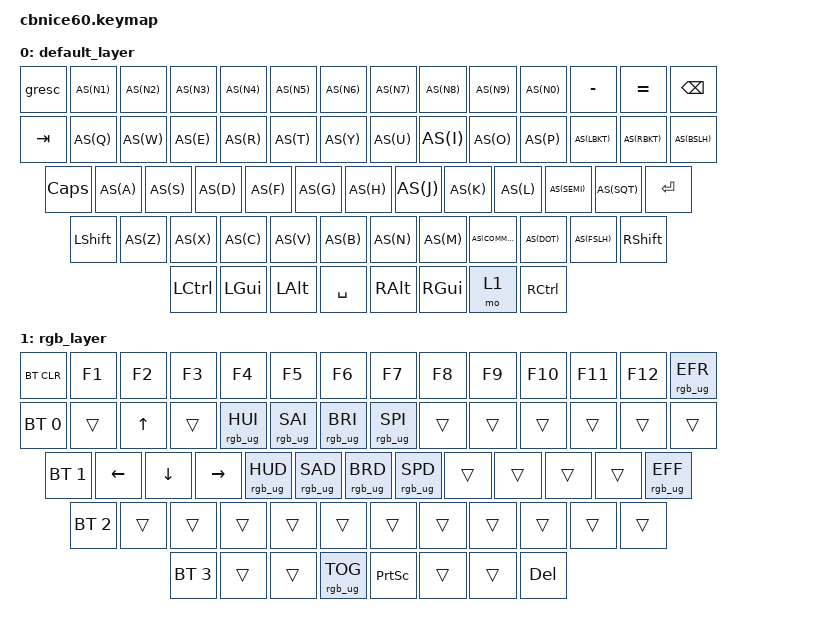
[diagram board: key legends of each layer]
/*
 * Copyright (c) 2021 Nick Winans
 *
 * SPDX-License-Identifier: MIT
 */

#include <behaviors.dtsi>
#include <dt-bindings/zmk/keys.h>
#include <dt-bindings/zmk/rgb.h>
#include <dt-bindings/zmk/bt.h>
#include <dt-bindings/zmk/outputs.h>
#include <dt-bindings/zmk/reset.h>
#include <dt-bindings/zmk/ext_power.h>

/ {
    behaviors {
        as: auto_shift {
            compatible = "zmk,behavior-hold-tap";
            label = "AUTO_SHIFT";
            #binding-cells = <2>;
            tapping_term_ms = <135>;
            quick_tap_ms = <0>;
            flavor = "tap-preferred";
            bindings = <&kp>, <&kp>;
        };
    };
	keymap {
		compatible = "zmk,keymap";
		
		default_layer {
// ------------------------------------------------------------------------------------------
// | ESC |  1  |  2  |  3  |  4  |  5  |  6  |  7  |  8  |  9  |  0  |  -  |  =  |   BKSP   |
// | TAB  |  Q  |  W  |  E  |  R  |  T  |  Y  |  U  |  I  |  O  |  P  |  [  |  ]  |   "|"   |
// | CAPS  |  A  |  S  |  D  |  F  |  G  |  H  |  J  |  K  |  L  |  ;  |  '  |     ENTER    |
// |  SHIFT  |  Z  |  X  |  C  |  V  |  B  |  N  |  M  |  ,  |  .  |  /  |      SHIFT       |
// |  CTL  |  WIN  |  ALT  |            SPACE              |  ALT  |  WIN  |  MO(1) |  CTL  |
// ------------------------------------------------------------------------------------------
			bindings = <
	&gresc  AS(N1) AS(N2) AS(N3) AS(N4) AS(N5) AS(N6)  AS(N7) AS(N8)  AS(N9)  AS(N0) &kp MINUS &kp EQUAL  &kp BSPC
	&kp TAB AS(Q) AS(W) AS(E) AS(R) AS(T) AS(Y) AS(U) AS(I) AS(O) AS(P) AS(LBKT)  AS(RBKT) AS(BSLH)
	&kp CLCK  AS(A) AS(S) AS(D) AS(F) AS(G) AS(H) AS(J) AS(K) AS(L) AS(SEMI) AS(SQT)           &kp RET
	&kp LSHFT   AS(Z) AS(X) AS(C) AS(V) AS(B) AS(N) AS(M) AS(COMMA) AS(DOT) AS(FSLH)           &kp RSHFT
	&kp LCTRL &kp LGUI &kp LALT             &kp SPACE                     &kp RALT  &kp RGUI  &mo 1   &kp RCTRL
			>;
		};

		rgb_layer {
// ------------------------------------------------------------------------------------------------
// | BT CLR | F1  | F2  | F3  | F4  | F5  | F6  | F7  | F8  | F9  | F10  | F11 | F12 | EFFECT REV |
// |  BT 1   |   |  UP |   | HUEUP | SATUP | BRIUP | SPDUP |   |     |    |     |     |           |
// |   BT 2   | LT |  DN  | RT | HUEDN | SATDN | BRIDN | SPDDN |   |     |   |     |  EFFECT FORW |
// |    BT 3     |     |      |      |     |     |     |     |     |     |     |                  |
// |   BT 4  |      |      |             TOG RGB                | PRT SCR |       |       |  DEL  |
// ------------------------------------------------------------------------------------------------
			bindings = <
	&bt BT_CLR   &kp F1    &kp F2    &kp F3  &kp F4           &kp F5          &kp F6          &kp F7          &kp F8   &kp F9   &kp F10  &kp F11 &kp F12  &rgb_ug RGB_EFR
	&bt BT_SEL 0  &trans    &kp UP    &trans  &rgb_ug RGB_HUI  &rgb_ug RGB_SAI &rgb_ug RGB_BRI &rgb_ug RGB_SPI  &trans   &trans   &trans   &trans  &trans          &trans 
	&bt BT_SEL 1   &kp LEFT  &kp DOWN  &kp RIGHT &rgb_ug RGB_HUD &rgb_ug RGB_SAD &rgb_ug RGB_BRD &rgb_ug RGB_SPD &trans   &trans   &trans   &trans        &rgb_ug RGB_EFF
	&bt BT_SEL 2    &trans    &trans    &trans   &trans          &trans          &trans          &trans          &trans   &trans   &trans                          &trans
	&bt BT_SEL 3  &trans   &trans                            &rgb_ug RGB_TOG                                      &kp PSCRN      &trans      &trans               &kp DEL
			>;
		};
	};
};
